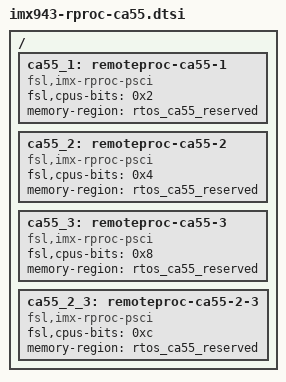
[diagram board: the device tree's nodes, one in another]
// SPDX-License-Identifier: (GPL-2.0 OR MIT)
/*
 * Copyright 2025 NXP
 */

/ {
	ca55_1: remoteproc-ca55-1 {
		compatible = "fsl,imx-rproc-psci";
		/* bitmask:0b000010, assign A55 Core 1 */
		fsl,cpus-bits = <0x2>;
		memory-region = <&rtos_ca55_reserved>;
	};

	ca55_2: remoteproc-ca55-2 {
		compatible = "fsl,imx-rproc-psci";
		/* bitmask:0b000100, assign A55 Core 2 */
		fsl,cpus-bits = <0x4>;
		memory-region = <&rtos_ca55_reserved>;
	};

	ca55_3: remoteproc-ca55-3 {
		compatible = "fsl,imx-rproc-psci";
		/* bitmask:0b001000, assign A55 Core 3 */
		fsl,cpus-bits = <0x8>;
		memory-region = <&rtos_ca55_reserved>;
	};

	ca55_2_3: remoteproc-ca55-2-3 {
		compatible = "fsl,imx-rproc-psci";
		/* bitmask:0b01100, assign A55 Core 2 and 3 */
		fsl,cpus-bits = <0xc>;
		memory-region = <&rtos_ca55_reserved>;
	};
};
